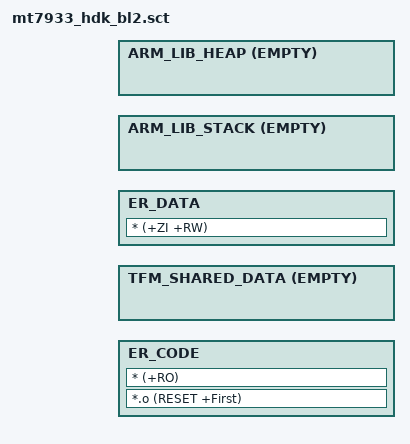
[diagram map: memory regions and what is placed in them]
#! armclang --target=arm-arm-none-eabi -march=armv8-m.main -E -xc

/*
 * Copyright (c) 2017-2019 Arm Limited. All rights reserved.
 *
 * Licensed under the Apache License, Version 2.0 (the "License");
 * you may not use this file except in compliance with the License.
 * You may obtain a copy of the License at
 *
 *     http://www.apache.org/licenses/LICENSE-2.0
 *
 * Unless required by applicable law or agreed to in writing, software
 * distributed under the License is distributed on an "AS IS" BASIS,
 * WITHOUT WARRANTIES OR CONDITIONS OF ANY KIND, either express or implied.
 * See the License for the specific language governing permissions and
 * limitations under the License.
 */

#include "region_defs.h"

LR_CODE BL2_CODE_START {
    ER_CODE BL2_CODE_START BL2_CODE_SIZE {
        *.o (RESET +First)
        * (+RO)
    }

    TFM_SHARED_DATA BL2_DATA_START ALIGN 32 EMPTY BOOT_TFM_SHARED_DATA_SIZE {
    }

    ER_DATA +0 BL2_DATA_SIZE {
        * (+ZI +RW)
    }

    /* MSP */
    ARM_LIB_STACK +0 ALIGN 32 EMPTY BL2_MSP_STACK_SIZE {
    }

    ARM_LIB_HEAP +0 ALIGN 8 EMPTY BL2_HEAP_SIZE {
    }
}
